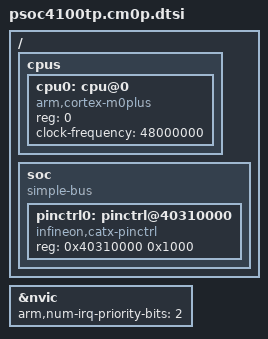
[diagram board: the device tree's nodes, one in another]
/*
 * Copyright (c) 2025 Infineon Technologies AG,
 * or an affiliate of Infineon Technologies AG.
 *
 * SPDX-License-Identifier: Apache-2.0
 */

#include <arm/armv6-m.dtsi>

/ {
	cpus {
		#address-cells = <1>;
		#size-cells = <0>;

		cpu0: cpu@0 {
			device_type = "cpu";
			compatible = "arm,cortex-m0plus";
			reg = <0>;
			clock-frequency = <48000000>;
		};
	};

	soc {
		compatible = "simple-bus";
		#address-cells = <1>;
		#size-cells = <1>;
		ranges;

		/* Pinctrl node for Infineon CAT2 SoC */
		pinctrl0: pinctrl@40310000 {
			compatible = "infineon,catx-pinctrl";
			reg = <0x40310000 0x1000>;
			status = "okay";
		};
	};
};

&nvic {
	arm,num-irq-priority-bits = <2>;
};
